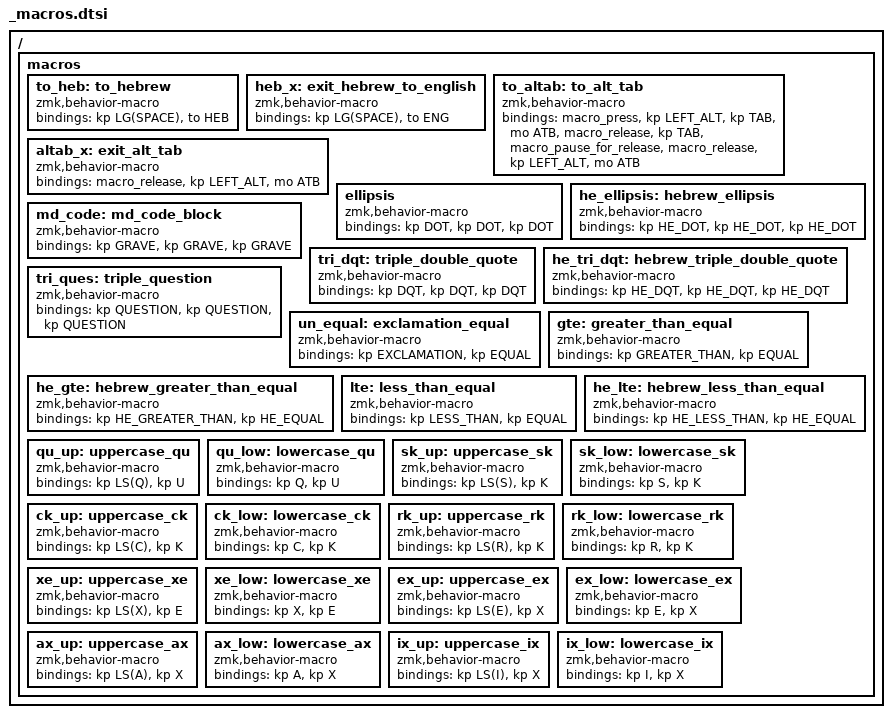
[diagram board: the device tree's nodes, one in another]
/ {    
    macros {
        to_heb: to_hebrew {
            compatible = "zmk,behavior-macro";
            #binding-cells = <0>;
            bindings = <&kp LG(SPACE) &to HEB>;
        };

        heb_x: exit_hebrew_to_english {
            compatible = "zmk,behavior-macro";
            #binding-cells = <0>;
            bindings = <&kp LG(SPACE) &to ENG>;
        };

        // Source: Discord
        // Author: Kites&Darts
        // https://discord.com/channels/719497620560543766/719909884769992755/1174453126716198942
        // https://github.com/damunchkn/zmk-config-fseli/blob/master/config/cradio.keymap
        to_altab: to_alt_tab {
            compatible = "zmk,behavior-macro";
            #binding-cells = <0>;
            bindings =
                <&macro_press &kp LEFT_ALT &kp TAB &mo ATB>,
                <&macro_release &kp TAB>,
                <&macro_pause_for_release>,
                <&macro_release &kp LEFT_ALT &mo ATB>;
        };

        // Source: https://github.com/zmkfirmware/zmk/issues/1806
        // Additional Ref: https://github.com/kaievns/zmk-config/blob/944ecf502cc73f186c83b6228f1225cf6ece5b61/config/cradio.keymap
        // to_altab: to_alt_tab {
        //     compatible = "zmk,behavior-macro";
        //     #binding-cells = <0>;
        //     bindings =
        //         <&macro_press &mo ATB>,
        //         <&macro_pause_for_release>,
        //         <&macro_release &kp LEFT_ALT>,
        //         <&macro_tap &to ENG>;
        // };

        altab_x: exit_alt_tab {
            compatible = "zmk,behavior-macro";
            #binding-cells = <0>;
            bindings = <&macro_release>, <&kp LEFT_ALT &mo ATB>;
        };

        ellipsis: ellipsis {
            compatible = "zmk,behavior-macro";
            #binding-cells = <0>;
            bindings = <&kp DOT &kp DOT &kp DOT>;
        };

        he_ellipsis: hebrew_ellipsis {
            compatible = "zmk,behavior-macro";
            #binding-cells = <0>;
            bindings = <&kp HE_DOT &kp HE_DOT &kp HE_DOT>;
        };

        md_code: md_code_block {
            compatible = "zmk,behavior-macro";
            #binding-cells = <0>;
            bindings = <&kp GRAVE &kp GRAVE &kp GRAVE>;
        };

        tri_dqt: triple_double_quote {
            compatible = "zmk,behavior-macro";
            #binding-cells = <0>;
            bindings = <&kp DQT &kp DQT &kp DQT>;
        };

        he_tri_dqt: hebrew_triple_double_quote {
            compatible = "zmk,behavior-macro";
            #binding-cells = <0>;
            bindings = <&kp HE_DQT &kp HE_DQT &kp HE_DQT>;
        };

        tri_ques: triple_question {
            compatible = "zmk,behavior-macro";
            #binding-cells = <0>;
            bindings = <&kp QUESTION &kp QUESTION &kp QUESTION>;
        };

        un_equal: exclamation_equal {
            compatible = "zmk,behavior-macro";
            #binding-cells = <0>;
            bindings = <&kp EXCLAMATION &kp EQUAL>;
        };

        gte: greater_than_equal {
            compatible = "zmk,behavior-macro";
            #binding-cells = <0>;
            bindings = <&kp GREATER_THAN &kp EQUAL>;
        };

        he_gte: hebrew_greater_than_equal {
            compatible = "zmk,behavior-macro";
            #binding-cells = <0>;
            bindings = <&kp HE_GREATER_THAN &kp HE_EQUAL>;
        };

        lte: less_than_equal {
            compatible = "zmk,behavior-macro";
            #binding-cells = <0>;
            bindings = <&kp LESS_THAN &kp EQUAL>;
        };

        he_lte: hebrew_less_than_equal {
            compatible = "zmk,behavior-macro";
            #binding-cells = <0>;
            bindings = <&kp HE_LESS_THAN &kp HE_EQUAL>;
        };

        qu_up: uppercase_qu {
            compatible = "zmk,behavior-macro";
            #binding-cells = <0>;
            bindings = <&kp LS(Q) &kp U>;
        };

        qu_low: lowercase_qu {
            compatible = "zmk,behavior-macro";
            #binding-cells = <0>;
            bindings = <&kp Q &kp U>;
        };

        sk_up: uppercase_sk {
            compatible = "zmk,behavior-macro";
            #binding-cells = <0>;
            bindings = <&kp LS(S) &kp K>;
        };

        sk_low: lowercase_sk {
            compatible = "zmk,behavior-macro";
            #binding-cells = <0>;
            bindings = <&kp S &kp K>;
        };

        ck_up: uppercase_ck {
            compatible = "zmk,behavior-macro";
            #binding-cells = <0>;
            bindings = <&kp LS(C) &kp K>;
        };

        ck_low: lowercase_ck {
            compatible = "zmk,behavior-macro";
            #binding-cells = <0>;
            bindings = <&kp C &kp K>;
        };

        rk_up: uppercase_rk {
            compatible = "zmk,behavior-macro";
            #binding-cells = <0>;
            bindings = <&kp LS(R) &kp K>;
        };

        rk_low: lowercase_rk {
            compatible = "zmk,behavior-macro";
            #binding-cells = <0>;
            bindings = <&kp R &kp K>;
        };

        xe_up: uppercase_xe {
            compatible = "zmk,behavior-macro";
            #binding-cells = <0>;
            bindings = <&kp LS(X) &kp E>;
        };

        xe_low: lowercase_xe {
            compatible = "zmk,behavior-macro";
            #binding-cells = <0>;
            bindings = <&kp X &kp E>;
        };

        ex_up: uppercase_ex {
            compatible = "zmk,behavior-macro";
            #binding-cells = <0>;
            bindings = <&kp LS(E) &kp X>;
        };

        ex_low: lowercase_ex {
            compatible = "zmk,behavior-macro";
            #binding-cells = <0>;
            bindings = <&kp E &kp X>;
        };

        ax_up: uppercase_ax {
            compatible = "zmk,behavior-macro";
            #binding-cells = <0>;
            bindings = <&kp LS(A) &kp X>;
        };

        ax_low: lowercase_ax {
            compatible = "zmk,behavior-macro";
            #binding-cells = <0>;
            bindings = <&kp A &kp X>;
        };

        ix_up: uppercase_ix {
            compatible = "zmk,behavior-macro";
            #binding-cells = <0>;
            bindings = <&kp LS(I) &kp X>;
        };

        ix_low: lowercase_ix {
            compatible = "zmk,behavior-macro";
            #binding-cells = <0>;
            bindings = <&kp I &kp X>;
        };
    };
};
